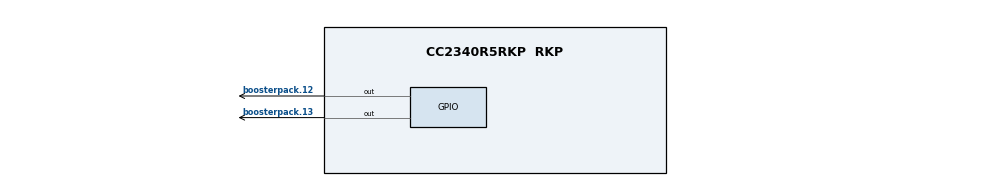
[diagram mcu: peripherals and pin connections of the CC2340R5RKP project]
/**
 * @cliArgs --board "/ti/boards/LP_EM_CC2340R5" --device "CC2340R5RKP" --part "Default" --package "RKP" --rtos "freertos" --product "simplelink_lowpower_f3_sdk@9.14.01.16"
 * @versions {"tool":"1.23.2+4156"}
 */

/**
 * Import the modules used in this configuration.
 */
const FreeRTOS = scripting.addModule("/freertos/FreeRTOS");
const GPIO     = scripting.addModule("/ti/drivers/GPIO");
const GPIO1    = GPIO.addInstance();
const GPIO2    = GPIO.addInstance();
const GPIO5    = GPIO.addInstance();
const GPIO6    = GPIO.addInstance();
const UART2    = scripting.addModule("/ti/drivers/UART2");
const UART21   = UART2.addInstance();
const Settings = scripting.addModule("/ti/posix/freertos/Settings");

/**
 * Write custom configuration values to the imported modules.
 */
GPIO1.$hardware = system.deviceData.board.components.LED_RED;
GPIO1.$name     = "CONFIG_GPIO_LED_0";

GPIO2.$name     = "CONFIG_GPIO_LED_1";
GPIO2.$hardware = system.deviceData.board.components.LED_GREEN;

GPIO5.$name           = "CONFIG_GPIO_BUTTON_0";
GPIO5.gpioPin.$assign = "boosterpack.13";
scripting.suppress("Connected to hardware,@@@.+?@@@ is connected to LaunchPad Button BTN-1 \\(Left\\) on the CC2340R5 Development Platform\\. Consider selecting it in \'use hardware\' above\\. @@@.+?@@@", GPIO5, "gpioPin");

GPIO6.$name           = "CONFIG_GPIO_BUTTON_1";
GPIO6.gpioPin.$assign = "boosterpack.12";
scripting.suppress("Connected to hardware,@@@.+?@@@ is connected to LaunchPad Button BTN-2 \\(Right\\) on the CC2340R5 Development Platform\\. Consider selecting it in \'use hardware\' above\\. @@@.+?@@@", GPIO6, "gpioPin");

UART21.$name     = "CONFIG_UART2_0";
UART21.$hardware = system.deviceData.board.components.XDS110UART;

const CCFG              = scripting.addModule("/ti/devices/CCFG", {}, false);
CCFG.ccfgTemplate.$name = "ti_devices_CCFG_CCFGCC23X0Template0";

/**
 * Pinmux solution for unlocked pins/peripherals. This ensures that minor changes to the automatic solver in a future
 * version of the tool will not impact the pinmux you originally saw.  These lines can be completely deleted in order to
 * re-solve from scratch.
 */
GPIO1.gpioPin.$suggestSolution            = "boosterpack.39";
GPIO2.gpioPin.$suggestSolution            = "boosterpack.40";
UART21.uart.$suggestSolution              = "UART0";
UART21.uart.dmaTxChannel.$suggestSolution = "DMA_CH1";
UART21.uart.dmaRxChannel.$suggestSolution = "DMA_CH0";
UART21.uart.txPin.$suggestSolution        = "boosterpack.4";
UART21.uart.rxPin.$suggestSolution        = "boosterpack.3";
